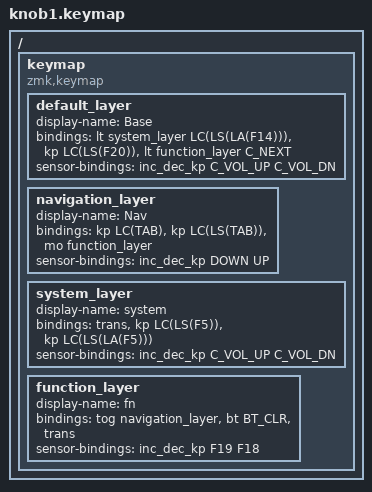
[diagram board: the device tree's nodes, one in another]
#include <behaviors.dtsi>
#include <dt-bindings/zmk/keys.h>
#include <dt-bindings/zmk/bt.h>
#include <dt-bindings/zmk/outputs.h>

#define default_layer 0
#define navigation_layer  1
#define system_layer 2
#define function_layer 3

/ {
    //behaviors {
    //    rot_0: rot_encoder {
    //        compatible = "zmk,behavior-sensor-rotate";
    //        #sensor-binding-cells = <0>;
    //        bindings = <&out OUT_TOG>, <&bt BT_CLR>;
    //    };
    //};

    keymap {
        compatible = "zmk,keymap";

        default_layer { // Layer 0
            display-name = "Base";
            bindings = <
                &lt system_layer LC(LS(LA(F14)))
                &kp LC(LS(F20))
                &lt function_layer C_NEXT
            >;
            sensor-bindings = <&inc_dec_kp C_VOL_UP C_VOL_DN>;
        };
        navigation_layer {
            display-name = "Nav";
            bindings = <
                &kp LC(TAB)
                &kp LC(LS(TAB))
                &mo function_layer
            >;
            sensor-bindings = <&inc_dec_kp DOWN UP>;
        };
        system_layer {
            display-name = "system";
            bindings = <
                &trans
                &kp LC(LS(F5))
                &kp LC(LS(LA(F5)))
            >;
            sensor-bindings = <&inc_dec_kp C_VOL_UP C_VOL_DN>;
        };
        function_layer {
            display-name = "fn";
            bindings = <
                &tog navigation_layer
                &bt BT_CLR
                &trans
            >;
            sensor-bindings = <&inc_dec_kp F19 F18>;
        };
    };
 };
